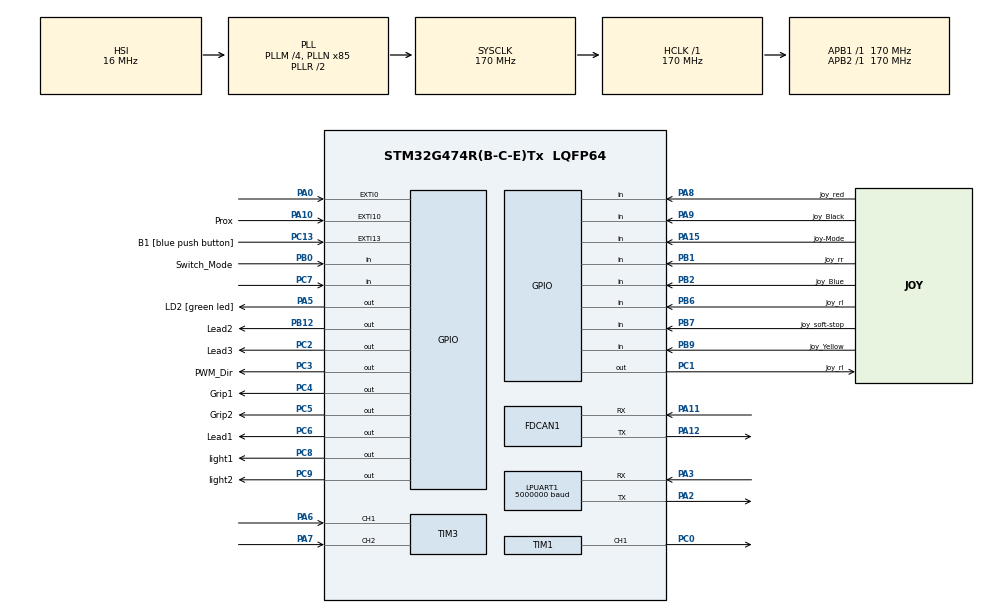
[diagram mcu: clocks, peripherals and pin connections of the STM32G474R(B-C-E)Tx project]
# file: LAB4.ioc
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ARM.CMSIS.5.7.0.CMSISJjCORE=true
ARM.CMSIS.5.7.0.CMSISJjDSP=Library
Dma.LPUART1_RX.1.Direction=DMA_PERIPH_TO_MEMORY
Dma.LPUART1_RX.1.EventEnable=DISABLE
Dma.LPUART1_RX.1.Instance=DMA1_Channel2
Dma.LPUART1_RX.1.MemDataAlignment=DMA_MDATAALIGN_BYTE
Dma.LPUART1_RX.1.MemInc=DMA_MINC_ENABLE
Dma.LPUART1_RX.1.Mode=DMA_NORMAL
Dma.LPUART1_RX.1.PeriphDataAlignment=DMA_PDATAALIGN_BYTE
Dma.LPUART1_RX.1.PeriphInc=DMA_PINC_DISABLE
Dma.LPUART1_RX.1.Polarity=HAL_DMAMUX_REQ_GEN_RISING
Dma.LPUART1_RX.1.Priority=DMA_PRIORITY_LOW
Dma.LPUART1_RX.1.RequestNumber=1
Dma.LPUART1_RX.1.SignalID=NONE
Dma.LPUART1_RX.1.SyncEnable=DISABLE
Dma.LPUART1_RX.1.SyncPolarity=HAL_DMAMUX_SYNC_NO_EVENT
Dma.LPUART1_RX.1.SyncRequestNumber=1
Dma.LPUART1_RX.1.SyncSignalID=NONE
Dma.LPUART1_TX.0.Direction=DMA_MEMORY_TO_PERIPH
Dma.LPUART1_TX.0.EventEnable=DISABLE
Dma.LPUART1_TX.0.Instance=DMA1_Channel1
Dma.LPUART1_TX.0.MemDataAlignment=DMA_MDATAALIGN_BYTE
Dma.LPUART1_TX.0.MemInc=DMA_MINC_ENABLE
Dma.LPUART1_TX.0.Mode=DMA_NORMAL
Dma.LPUART1_TX.0.PeriphDataAlignment=DMA_PDATAALIGN_BYTE
Dma.LPUART1_TX.0.PeriphInc=DMA_PINC_DISABLE
Dma.LPUART1_TX.0.Polarity=HAL_DMAMUX_REQ_GEN_RISING
Dma.LPUART1_TX.0.Priority=DMA_PRIORITY_LOW
Dma.LPUART1_TX.0.RequestNumber=1
Dma.LPUART1_TX.0.SignalID=NONE
Dma.LPUART1_TX.0.SyncEnable=DISABLE
Dma.LPUART1_TX.0.SyncPolarity=HAL_DMAMUX_SYNC_NO_EVENT
Dma.LPUART1_TX.0.SyncRequestNumber=1
Dma.LPUART1_TX.0.SyncSignalID=NONE
Dma.Request0=LPUART1_TX
Dma.Request1=LPUART1_RX
FDCAN1.CalculateBaudRateNominal=3541666
FDCAN1.CalculateTimeBitNominal=282
FDCAN1.CalculateTimeQuantumNominal=94.11764705882354
LPUART1.BaudRate=5000000
Mcu.Family=STM32G4
Mcu.Name=STM32G474R(B-C-E)Tx
Mcu.Package=LQFP64
NVIC.DMA1_Channel1_IRQn=true\:0\:0\:false\:false\:true\:false\:true\:true
NVIC.DMA1_Channel2_IRQn=true\:0\:0\:false\:false\:true\:false\:true\:true
NVIC.EXTI15_10_IRQn=true\:0\:0\:false\:false\:true\:true\:true\:true
NVIC.LPUART1_IRQn=true\:0\:0\:false\:false\:true\:true\:true\:true
NVIC.PriorityGroup=NVIC_PRIORITYGROUP_4
NVIC.TIM1_UP_TIM16_IRQn=true\:0\:0\:false\:false\:true\:true\:true\:true
NVIC.TIM20_UP_IRQn=true\:0\:0\:false\:false\:true\:true\:true\:true
PA0.GPIO_PuPd=GPIO_PULLUP
PA0.Signal=GPXTI0
PA10.GPIO_Label=Prox
PA10.Signal=GPXTI10
PA11.Mode=FDCAN_Activate
PA11.Signal=FDCAN1_RX
PA12.Mode=FDCAN_Activate
PA12.Signal=FDCAN1_TX
PA13.GPIO_Label=T_SWDIO
PA13.Signal=SYS_JTMS-SWDIO
PA14.GPIO_Label=T_SWCLK
PA14.Signal=SYS_JTCK-SWCLK
PA15.GPIO_Label=Joy-Mode
PA15.GPIO_PuPd=GPIO_PULLUP
PA15.Signal=GPIO_Input
PA2.GPIO_Speed=GPIO_SPEED_FREQ_VERY_HIGH
PA2.Mode=Asynchronous
PA2.Signal=LPUART1_TX
PA3.GPIO_Speed=GPIO_SPEED_FREQ_VERY_HIGH
PA3.Mode=Asynchronous
PA3.Signal=LPUART1_RX
PA5.GPIO_Label=LD2 [green led]
PA5.Signal=GPIO_Output
PA6.Signal=S_TIM3_CH1
PA7.Signal=S_TIM3_CH2
PA8.GPIO_Label=Joy_red
PA8.GPIO_PuPd=GPIO_PULLUP
PA8.Signal=GPIO_Input
PA9.GPIO_Label=Joy_Black
PA9.GPIO_PuPd=GPIO_PULLUP
PA9.Signal=GPIO_Input
PB0.GPIO_Label=Switch_Mode
PB0.GPIO_PuPd=GPIO_PULLUP
PB0.Signal=GPIO_Input
PB1.GPIO_Label=Joy_rr
PB1.GPIO_PuPd=GPIO_PULLUP
PB1.Signal=GPIO_Input
PB12.GPIO_Label=Lead2
PB12.Signal=GPIO_Output
PB2.GPIO_Label=Joy_Blue
PB2.GPIO_PuPd=GPIO_PULLUP
PB2.Signal=GPIO_Input
PB3.GPIO_Label=T_SWO
PB3.Signal=SYS_JTDO-SWO
PB6.GPIO_Label=Joy_rl
PB6.GPIO_PuPd=GPIO_PULLUP
PB6.Signal=GPIO_Input
PB7.GPIO_Label=Joy_soft-stop
PB7.GPIO_PuPd=GPIO_PULLUP
PB7.Signal=GPIO_Input
PB9.GPIO_Label=Joy_Yellow
PB9.GPIO_PuPd=GPIO_PULLUP
PB9.Signal=GPIO_Input
PC0.Signal=S_TIM1_CH1
PC1.GPIO_Label=Joy_rl
PC1.GPIO_PuPd=GPIO_PULLUP
PC1.Signal=GPIO_Output
PC13.GPIO_Label=B1 [blue push button]
PC13.Signal=GPXTI13
PC14-OSC32_IN.GPIO_Label=RCC_OSC32_IN
PC14-OSC32_IN.Signal=RCC_OSC32_IN
PC15-OSC32_OUT.GPIO_Label=RCC_OSC32_OUT
PC15-OSC32_OUT.Signal=RCC_OSC32_OUT
PC2.GPIO_Label=Lead3
PC2.Signal=GPIO_Output
PC3.GPIO_Label=PWM_Dir
PC3.Signal=GPIO_Output
PC4.GPIO_Label=Grip1
PC4.Signal=GPIO_Output
PC5.GPIO_Label=Grip2
PC5.Signal=GPIO_Output
PC6.GPIO_Label=Lead1
PC6.Signal=GPIO_Output
PC7.GPIO_PuPd=GPIO_NOPULL
PC7.Signal=GPIO_Input
PC8.GPIO_Label=light1
PC8.Signal=GPIO_Output
PC9.GPIO_Label=light2
PC9.Signal=GPIO_Output
PF0-OSC_IN.GPIO_Label=RCC_OSC_IN
PF0-OSC_IN.Signal=RCC_OSC_IN
PF1-OSC_OUT.GPIO_Label=RCC_OSC_OUT
PF1-OSC_OUT.Signal=RCC_OSC_OUT
ProjectManager.HeapSize=0x200
ProjectManager.StackSize=0x400
ProjectManager.TargetToolchain=STM32CubeIDE
RCC.ADC12Freq_Value=170000000
RCC.ADC345Freq_Value=170000000
RCC.AHBFreq_Value=170000000
RCC.APB1Freq_Value=170000000
RCC.APB1TimFreq_Value=170000000
RCC.APB2Freq_Value=170000000
RCC.APB2TimFreq_Value=170000000
RCC.CortexFreq_Value=170000000
RCC.EXTERNAL_CLOCK_VALUE=12288000
RCC.HCLKFreq_Value=170000000
RCC.HSE_VALUE=24000000
RCC.HSI48_VALUE=48000000
RCC.HSI_VALUE=16000000
RCC.LSE_VALUE=32768
RCC.PLLM=RCC_PLLM_DIV4
RCC.PLLN=85
RCC.RTCClockSelection=RCC_RTCCLKSOURCE_LSE
RCC.SYSCLKFreq_VALUE=170000000
RCC.SYSCLKSource=RCC_SYSCLKSOURCE_PLLCLK
RCC.USBFreq_Value=170000000
RCC.VCOOutputFreq_Value=340000000
SH.S_TIM1_CH1.0=TIM1_CH1,PWM Generation1 CH1
SH.S_TIM3_CH1.0=TIM3_CH1,Encoder_Interface
SH.S_TIM3_CH2.0=TIM3_CH2,Encoder_Interface
TIM1.Channel-PWM\ Generation1\ CH1=TIM_CHANNEL_1
TIM1.PeriodNoDither=42500
TIM1.Prescaler=1
TIM16.Channel=TIM_CHANNEL_1
TIM16.PeriodNoDither=1145
TIM16.Prescaler=169
TIM2.Prescaler=169
TIM20.PeriodNoDither=500
TIM20.Prescaler=169
TIM3.EncoderMode=TIM_ENCODERMODE_TI12
VP_ARM.CMSIS_VS_CMSISJjCORE_5.4.0_5.7.0.Mode=CMSISJjCORE
VP_ARM.CMSIS_VS_CMSISJjDSP_1.8.0_5.7.0.Mode=CMSISJjDSP
VP_SYS_VS_DBSignals.Mode=DisableDeadBatterySignals
VP_TIM16_VS_ClockSourceINT.Mode=Enable_Timer
VP_TIM16_VS_OPM.Mode=OPM_bit
VP_TIM16_VS_no_output1.Mode=Output Compare1 No Output
VP_TIM1_VS_ClockSourceINT.Mode=Internal
VP_TIM20_VS_ClockSourceINT.Mode=Internal
VP_TIM2_VS_ClockSourceINT.Mode=Internal
board=NUCLEO-G474RE

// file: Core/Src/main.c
/* USER CODE BEGIN Header */
/**
  ******************************************************************************
  * @file           : main.c
  * @brief          : LAB4 — 3-lab experimental setup (Kalman / Inner Loop / Cascade)
  *                   Parameters received from MATLAB via Waijung UART (179-byte packet).
  *
  * Live Expression variables:
  *   lab.lab_select        — active lab (1/2/3)
  *   encoder.encoder_rad   — actual position [rad]
  *   Kalman.X[0..3]        — Kalman states
  *   vout                  — controller voltage output [V]
  *   actual_error          — absolute position error [deg]
  ******************************************************************************
  */
/* USER CODE END Header */
#include "main.h"
#include "dma.h"
#include "fdcan.h"
#include "usart.h"
#include "tim.h"
#include "gpio.h"

/* USER CODE BEGIN Includes */
#include "LAB_Manager.h"
/* USER CODE END Includes */

/* USER CODE BEGIN PD */
/* All lab parameters and defines are in lab_config.h and LAB_Manager.h */
/* USER CODE END PD */

/* USER CODE BEGIN PV */
/* All variables are owned by LAB_Manager.c */
/* USER CODE END PV */

void SystemClock_Config(void);

int main(void)
{

  /* MCU Configuration--------------------------------------------------------*/

  /* Reset of all peripherals, Initializes the Flash interface and the Systick. */
  HAL_Init();

  /* Configure the system clock */
  SystemClock_Config();

  /* Initialize all configured peripherals */
  MX_GPIO_Init();
  MX_DMA_Init();
  MX_TIM16_Init();
  MX_TIM1_Init();
  MX_TIM3_Init();
  MX_TIM20_Init();
  MX_TIM2_Init();
  MX_LPUART1_UART_Init();
  MX_FDCAN1_Init();
  /* USER CODE BEGIN 2 */
    LAB_Init();
  /* USER CODE END 2 */

  /* Infinite loop */
    while (1)
    {

    /* USER CODE BEGIN 3 */
        LAB_MainLoop();
    }
  /* USER CODE END 3 */
}

void SystemClock_Config(void)
{
  RCC_OscInitTypeDef RCC_OscInitStruct = {0};
  RCC_ClkInitTypeDef RCC_ClkInitStruct = {0};

  /** Configure the main internal regulator output voltage
  */
  HAL_PWREx_ControlVoltageScaling(PWR_REGULATOR_VOLTAGE_SCALE1_BOOST);

  /** Initializes the RCC Oscillators according to the specified parameters
  * in the RCC_OscInitTypeDef structure.
  */
  RCC_OscInitStruct.OscillatorType = RCC_OSCILLATORTYPE_HSI;
  RCC_OscInitStruct.HSIState = RCC_HSI_ON;
  RCC_OscInitStruct.HSICalibrationValue = RCC_HSICALIBRATION_DEFAULT;
  RCC_OscInitStruct.PLL.PLLState = RCC_PLL_ON;
  RCC_OscInitStruct.PLL.PLLSource = RCC_PLLSOURCE_HSI;
  RCC_OscInitStruct.PLL.PLLM = RCC_PLLM_DIV4;
  RCC_OscInitStruct.PLL.PLLN = 85;
  RCC_OscInitStruct.PLL.PLLP = RCC_PLLP_DIV2;
  RCC_OscInitStruct.PLL.PLLQ = RCC_PLLQ_DIV2;
  RCC_OscInitStruct.PLL.PLLR = RCC_PLLR_DIV2;
  if (HAL_RCC_OscConfig(&RCC_OscInitStruct) != HAL_OK)
  {
    Error_Handler();
  }

  /** Initializes the CPU, AHB and APB buses clocks
  */
  RCC_ClkInitStruct.ClockType = RCC_CLOCKTYPE_HCLK|RCC_CLOCKTYPE_SYSCLK
                              |RCC_CLOCKTYPE_PCLK1|RCC_CLOCKTYPE_PCLK2;
  RCC_ClkInitStruct.SYSCLKSource = RCC_SYSCLKSOURCE_PLLCLK;
  RCC_ClkInitStruct.AHBCLKDivider = RCC_SYSCLK_DIV1;
  RCC_ClkInitStruct.APB1CLKDivider = RCC_HCLK_DIV1;
  RCC_ClkInitStruct.APB2CLKDivider = RCC_HCLK_DIV1;

  if (HAL_RCC_ClockConfig(&RCC_ClkInitStruct, FLASH_LATENCY_4) != HAL_OK)
  {
    Error_Handler();
  }
}

/* USER CODE BEGIN 4 */
/* Control loop ISR, GPIO callback, and all lab logic are in LAB_Manager.c */
/* USER CODE END 4 */

void Error_Handler(void)
{
  __disable_irq();
  while (1)
  {
  }
}
